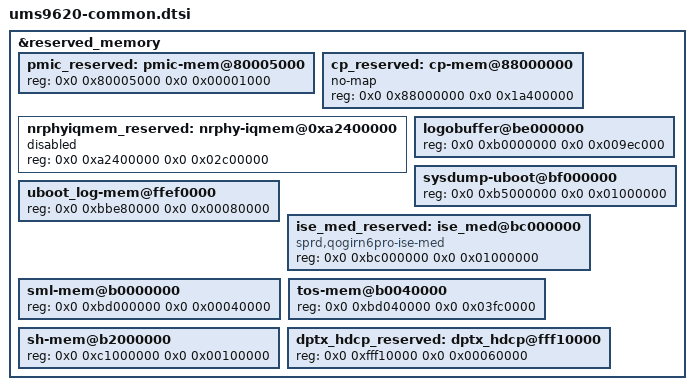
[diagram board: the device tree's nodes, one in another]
// SPDX-License-Identifier: (Licenseref-Unisoc-General-1.0 OR GPL-2.0-only)
/*
 * ums9620-common.dtsi - Unisoc platform device
 *
 * Copyright 2022 Unisoc(Shanghai) Technologies Co.Ltd
 *
 * Licensed under the Unisoc General Software License, version 1.0 (the
 * License);
 * you may not use this file except in compliance with the License.
 * You may obtain a copy of the License at
 * https://www.unisoc.com/en_us/license/UNISOC_GENERAL_LICENSE_V1.0-EN_US
 * Software distributed under the License is distributed on an "AS IS" BASIS,
 * WITHOUT WARRANTIES OF ANY KIND, either express or implied.
 * See the Unisoc General Software License, version 1.0 for more details.
 *
 * Alternatively you can use and distribute this file under the terms of the
 * GNU General Public License version 2, provided that it has to be used
 *  (including but not limited to combining, linking) with any other file under
 * the GNU General Public License version 2 on platforms that use Unisoc Chips.
 */

#include "modem-5g-common.dtsi"
&reserved_memory {
    pmic_reserved: pmic-mem@80005000 {
			reg = <0x0 0x80005000 0x0 0x00001000>;
	};

	cp_reserved: cp-mem@88000000 {
		no-map;
		reg = <0x0 0x88000000 0x0 0x1a400000>;
	};

	nrphyiqmem_reserved: nrphy-iqmem@0xa2400000 {
		reg = <0x0 0xa2400000 0x0 0x02c00000>;
		status = "disabled";
	};
	/* the @addr value is not accurate on N6Pro, please refer to the reg value */
	logobuffer@be000000 {
		reg = <0x0 0xb0000000 0x0 0x009e4000>;
	};

	/* Only for userdebug, will be removed in user mode by lk */
	/* the @addr value is not accurate on N6Pro, please refer to the reg value */
	sysdump-uboot@bf000000 {
		reg = <0x0 0xb5000000 0x0 0x01000000>;
	};

	/* The uboot_log_reserved node is added in lk. base:0xbbe80000, size:0x80000 */
	/* the @addr value is not accurate on N6Pro, please refer to the reg value */
	uboot_log-mem@ffef0000 {
		reg = <0x0 0xbbe80000 0x0 0x00080000>;
	};

	ise_med_reserved: ise_med@bc000000 {
		compatible = "sprd,qogirn6pro-ise-med";
		reg = <0x0 0xbc000000 0x0 0x01000000>;
	};

	/* must be 1M aligned */
	/* the @addr value is not accurate on N6Pro, please refer to the reg value */
	sml-mem@b0000000 {
		reg = <0x0 0xbd000000 0x0 0x00040000>;
	};

	/* the reg values may be not accurate, they have been fixed in lk !!! */
	/* the @addr value is not accurate on N6Pro, please refer to the reg value */
	tos-mem@b0040000 {
		reg = <0x0 0xbd040000 0x0 0x03fc0000>;
	};

	/* the @addr value is not accurate on N6Pro, please refer to the reg value */
	sh-mem@b2000000{
		reg = <0x0 0xc1000000 0x0 0x00100000>;
	};

	dptx_hdcp_reserved: dptx_hdcp@fff10000 {
		reg = <0x0 0xfff10000 0x0 0x00060000>;
	};

	logobuffer@be000000 {
		reg = <0x0 0xb0000000 0x0 0x009ec000>;
	};
};

